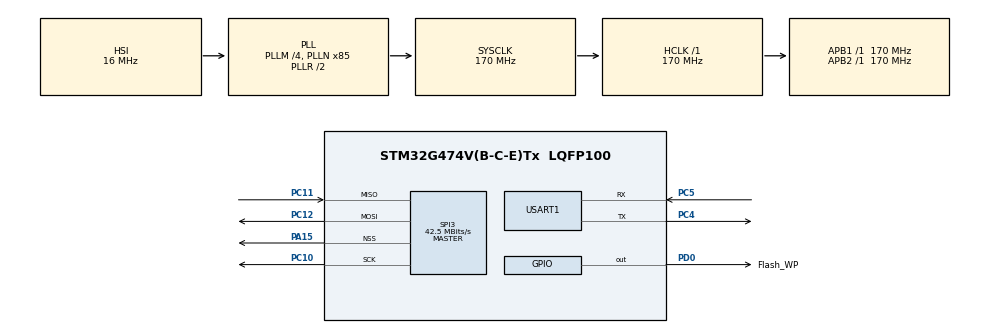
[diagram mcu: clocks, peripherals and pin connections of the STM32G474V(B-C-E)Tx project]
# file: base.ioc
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Mcu.Family=STM32G4
Mcu.Name=STM32G474V(B-C-E)Tx
Mcu.Package=LQFP100
NVIC.PriorityGroup=NVIC_PRIORITYGROUP_4
PA13.Mode=Trace_Asynchronous_SW
PA13.Signal=SYS_JTMS-SWDIO
PA14.Mode=Trace_Asynchronous_SW
PA14.Signal=SYS_JTCK-SWCLK
PA15.Mode=NSS_Signal_Hard_Output
PA15.Signal=SPI3_NSS
PA15.Stacked=true
PB3.Mode=Trace_Asynchronous_SW
PB3.Signal=SYS_JTDO-SWO
PC10.Mode=Full_Duplex_Master
PC10.Signal=SPI3_SCK
PC11.Mode=Full_Duplex_Master
PC11.Signal=SPI3_MISO
PC12.Mode=Full_Duplex_Master
PC12.Signal=SPI3_MOSI
PC14-OSC32_IN.Mode=LSE-External-Oscillator
PC14-OSC32_IN.Signal=RCC_OSC32_IN
PC15-OSC32_OUT.Mode=LSE-External-Oscillator
PC15-OSC32_OUT.Signal=RCC_OSC32_OUT
PC4.Mode=Asynchronous
PC4.Signal=USART1_TX
PC5.Mode=Asynchronous
PC5.Signal=USART1_RX
PD0.GPIO_Label=Flash_WP
PD0.Signal=GPIO_Output
PD0.Stacked=true
PF0-OSC_IN.Mode=HSE-External-Oscillator
PF0-OSC_IN.Signal=RCC_OSC_IN
PF1-OSC_OUT.Mode=HSE-External-Oscillator
PF1-OSC_OUT.Signal=RCC_OSC_OUT
ProjectManager.HeapSize=0x200
ProjectManager.StackSize=0x400
ProjectManager.TargetToolchain=STM32CubeIDE
RCC.ADC12Freq_Value=170000000
RCC.ADC345Freq_Value=170000000
RCC.AHBFreq_Value=170000000
RCC.APB1Freq_Value=170000000
RCC.APB1TimFreq_Value=170000000
RCC.APB2Freq_Value=170000000
RCC.APB2TimFreq_Value=170000000
RCC.CortexFreq_Value=170000000
RCC.EXTERNAL_CLOCK_VALUE=12288000
RCC.HCLKFreq_Value=170000000
RCC.HSE_VALUE=20000000
RCC.HSI48_VALUE=48000000
RCC.HSI_VALUE=16000000
RCC.PLLM=RCC_PLLM_DIV4
RCC.PLLN=85
RCC.SYSCLKFreq_VALUE=170000000
RCC.SYSCLKSource=RCC_SYSCLKSOURCE_PLLCLK
RCC.USBFreq_Value=170000000
RCC.VCOOutputFreq_Value=340000000
SPI3.BaudRatePrescaler=SPI_BAUDRATEPRESCALER_4
SPI3.CalculateBaudRate=42.5 MBits/s
SPI3.Direction=SPI_DIRECTION_2LINES
SPI3.Mode=SPI_MODE_MASTER
SPI3.VirtualNSS=VM_NSSHARD
SPI3.VirtualType=VM_MASTER
USART1.VirtualMode-Asynchronous=VM_ASYNC
VP_SYS_VS_DBSignals.Mode=DisableDeadBatterySignals
board=custom

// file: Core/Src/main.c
/* USER CODE BEGIN Header */
/**
  ******************************************************************************
  * @file           : main.c
  * @brief          : Main program body
  ******************************************************************************
  * @attention
  *
  * Copyright (c) 2023 STMicroelectronics.
  * All rights reserved.
  *
  * This software is licensed under terms that can be found in the LICENSE file
  * in the root directory of this software component.
  * If no LICENSE file comes with this software, it is provided AS-IS.
  *
  ******************************************************************************
  */
/* USER CODE END Header */
#include "main.h"
#include "spi.h"
#include "usart.h"
#include "gpio.h"

/* USER CODE BEGIN Includes */
#include "menu.h"

/* USER CODE END Includes */

void SystemClock_Config(void);

int main(void)
{

  /* MCU Configuration--------------------------------------------------------*/

  /* Reset of all peripherals, Initializes the Flash interface and the Systick. */
  HAL_Init();

  /* Configure the system clock */
  SystemClock_Config();

  /* Initialize all configured peripherals */
  MX_GPIO_Init();
  MX_SPI3_Init();
  MX_USART1_UART_Init();
  /* USER CODE BEGIN 2 */
  init_menu();
  /* USER CODE END 2 */

  /* Infinite loop */
  /* USER CODE BEGIN WHILE */
  while (1)
  {
    menu_loop();
    /* USER CODE END WHILE */

  }
}

void SystemClock_Config(void)
{
  RCC_OscInitTypeDef RCC_OscInitStruct = {0};
  RCC_ClkInitTypeDef RCC_ClkInitStruct = {0};

  /** Configure the main internal regulator output voltage
  */
  HAL_PWREx_ControlVoltageScaling(PWR_REGULATOR_VOLTAGE_SCALE1_BOOST);

  /** Initializes the RCC Oscillators according to the specified parameters
  * in the RCC_OscInitTypeDef structure.
  */
  RCC_OscInitStruct.OscillatorType = RCC_OSCILLATORTYPE_HSI;
  RCC_OscInitStruct.HSIState = RCC_HSI_ON;
  RCC_OscInitStruct.HSICalibrationValue = RCC_HSICALIBRATION_DEFAULT;
  RCC_OscInitStruct.PLL.PLLState = RCC_PLL_ON;
  RCC_OscInitStruct.PLL.PLLSource = RCC_PLLSOURCE_HSI;
  RCC_OscInitStruct.PLL.PLLM = RCC_PLLM_DIV4;
  RCC_OscInitStruct.PLL.PLLN = 85;
  RCC_OscInitStruct.PLL.PLLP = RCC_PLLP_DIV2;
  RCC_OscInitStruct.PLL.PLLQ = RCC_PLLQ_DIV2;
  RCC_OscInitStruct.PLL.PLLR = RCC_PLLR_DIV2;
  if (HAL_RCC_OscConfig(&RCC_OscInitStruct) != HAL_OK)
  {
    Error_Handler();
  }

  /** Initializes the CPU, AHB and APB buses clocks
  */
  RCC_ClkInitStruct.ClockType = RCC_CLOCKTYPE_HCLK|RCC_CLOCKTYPE_SYSCLK
                              |RCC_CLOCKTYPE_PCLK1|RCC_CLOCKTYPE_PCLK2;
  RCC_ClkInitStruct.SYSCLKSource = RCC_SYSCLKSOURCE_PLLCLK;
  RCC_ClkInitStruct.AHBCLKDivider = RCC_SYSCLK_DIV1;
  RCC_ClkInitStruct.APB1CLKDivider = RCC_HCLK_DIV1;
  RCC_ClkInitStruct.APB2CLKDivider = RCC_HCLK_DIV1;

  if (HAL_RCC_ClockConfig(&RCC_ClkInitStruct, FLASH_LATENCY_4) != HAL_OK)
  {
    Error_Handler();
  }
}

void Error_Handler(void)
{
  __disable_irq();
  while (1)
  {
  }
}
